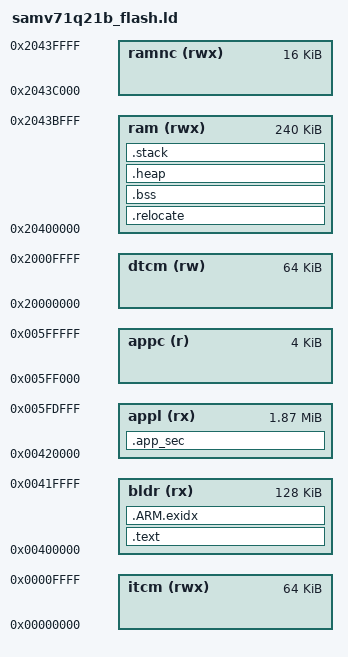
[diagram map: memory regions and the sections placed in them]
/**
 * \file
 *
 * \brief GCC linker script (flash) for ATSAMV71Q21B
 *
 * Copyright (c) 2017 Atmel Corporation, a wholly owned subsidiary of Microchip Technology Inc.
 *
 * \license_start
 *
 * \page License
 *
 * Licensed under the Apache License, Version 2.0 (the "License");
 * you may not use this file except in compliance with the License.
 * You may obtain a copy of the License at
 *
 *   http://www.apache.org/licenses/LICENSE-2.0
 *
 * Unless required by applicable law or agreed to in writing, software
 * distributed under the License is distributed on an "AS IS" BASIS,
 * WITHOUT WARRANTIES OR CONDITIONS OF ANY KIND, either express or implied.
 * See the License for the specific language governing permissions and
 * limitations under the License.
 *
 * \license_stop
 *
 */

/*------------------------------------------------------------------------------
 *      Linker script for running in internal FLASH on the ATSAMV71Q21B
 *----------------------------------------------------------------------------*/

OUTPUT_FORMAT("elf32-littlearm", "elf32-littlearm", "elf32-littlearm")
OUTPUT_ARCH(arm)

/* Memory Spaces Definitions */
MEMORY
{
  itcm (rwx)   : ORIGIN = 0x00000000, LENGTH = 0x00010000
	bldr (rx)    : ORIGIN = 0x00400000, LENGTH = 0x00020000
	appl (rx)    : ORIGIN = 0x00420000, LENGTH = 0x001DE000
	appc (r)     : ORIGIN = 0x005FF000, LENGTH = 0x00001000
	dtcm (rw)    : ORIGIN = 0x20000000, LENGTH = 0x00010000
	ram (rwx)    : ORIGIN = 0x20400000, LENGTH = 0x0003C000
  ramnc (rwx)  : ORIGIN = 0x2043C000, LENGTH = 0x00004000
}

HEAP_SIZE  = 0x0;
STACK_SIZE = 0x1000;

/* Section Definitions */
SECTIONS
{
    .text :
    {
        . = ALIGN(4);
        _sfixed = .;
        KEEP(*(.vectors .vectors.*))
        *(.text .text.* .gnu.linkonce.t.*)
        *(.glue_7t) *(.glue_7)
        *(.rodata .rodata* .gnu.linkonce.r.*)
        *(.ARM.extab* .gnu.linkonce.armextab.*)

        /* Support C constructors, and C destructors in both user code
           and the C library. This also provides support for C++ code. */
        . = ALIGN(4);
        KEEP(*(.init))
        . = ALIGN(4);
        __preinit_array_start = .;
        KEEP (*(.preinit_array))
        __preinit_array_end = .;

        . = ALIGN(4);
        __init_array_start = .;
        KEEP (*(SORT(.init_array.*)))
        KEEP (*(.init_array))
        __init_array_end = .;

        . = ALIGN(0x4);
        KEEP (*crtbegin.o(.ctors))
        KEEP (*(EXCLUDE_FILE (*crtend.o) .ctors))
        KEEP (*(SORT(.ctors.*)))
        KEEP (*crtend.o(.ctors))

        . = ALIGN(4);
        KEEP(*(.fini))

        . = ALIGN(4);
        __fini_array_start = .;
        KEEP (*(.fini_array))
        KEEP (*(SORT(.fini_array.*)))
        __fini_array_end = .;

        KEEP (*crtbegin.o(.dtors))
        KEEP (*(EXCLUDE_FILE (*crtend.o) .dtors))
        KEEP (*(SORT(.dtors.*)))
        KEEP (*crtend.o(.dtors))

        . = ALIGN(4);
        _efixed = .;            /* End of text section */
    } > bldr

    /* .ARM.exidx is sorted, so has to go in its own output section.  */
    PROVIDE_HIDDEN (__exidx_start = .);
    .ARM.exidx :
    {
      *(.ARM.exidx* .gnu.linkonce.armexidx.*)
    } > bldr
    PROVIDE_HIDDEN (__exidx_end = .);

    . = ALIGN(4);
    _etext = .;

	.app_sec :
	{
		. = ALIGN(4);
		_app_stackAddr = .;
		_app_vtorAddr = . + 4;
	} > appl

    .relocate : AT (_etext)
    {
        . = ALIGN(4);
        _srelocate = .;
        *(.ramfunc .ramfunc.*);
        *(.code_TCM .code_TCM.*);
        *(.data .data.*);
        . = ALIGN(4);
        _erelocate = .;
    } > ram

    /* .bss section which is used for uninitialized data */
    .bss (NOLOAD) :
    {
        . = ALIGN(4);
        _sbss = . ;
        _szero = .;
        *(.bss .bss.*)
        *(COMMON)
        . = ALIGN(4);
        _ebss = . ;
        _ezero = .;
    } > ram

    /* heap section */
    .heap (NOLOAD):
    {
        . = ALIGN(8);
         _sheap = .;
        . = . + HEAP_SIZE;
        . = ALIGN(8);
        _eheap = .;
    } > ram

    /* stack section */
    .stack (NOLOAD):
    {
        . = ALIGN(8);
        _sstack = .;
        . = . + STACK_SIZE;
        . = ALIGN(8);
        _estack = .;
    } > ram

    . = ALIGN(4);
    _end = . ;

	_ram_start_  = ORIGIN(ram);
  _ram_end_    = _ram_start_ + LENGTH(ram) - 1 ;
	_appl_start_ = ORIGIN(appl);
	_appl_end_   = _appl_start_ + LENGTH(appl) - 1;
  _dtcm_start_ = ORIGIN(dtcm);
  _dtcm_end_   = _dtcm_start_ + LENGTH(dtcm) - 1;

	_app_chkSumAddr = ORIGIN(appc) + LENGTH(appc) - 4;
	_app_chkSumLen  = _app_chkSumAddr - 4;
}
